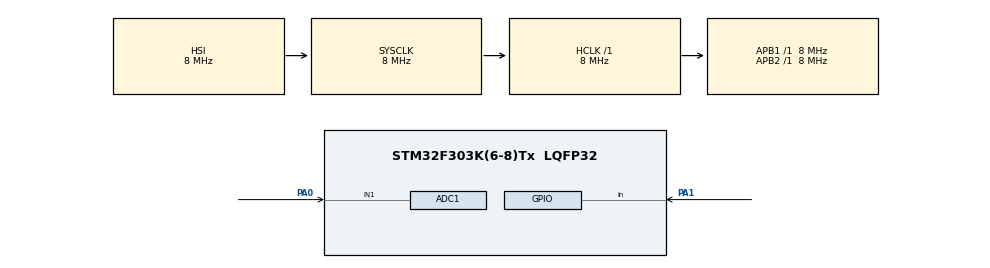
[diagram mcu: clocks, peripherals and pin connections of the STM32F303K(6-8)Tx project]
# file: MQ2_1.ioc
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ADC1.Channel-0\#ChannelRegularConversion=ADC_CHANNEL_1
ADC1.NbrOfConversionFlag=1
ADC1.Offset-0\#ChannelRegularConversion=0
ADC1.OffsetNumber-0\#ChannelRegularConversion=ADC_OFFSET_NONE
ADC1.Rank-0\#ChannelRegularConversion=1
ADC1.SamplingTime-0\#ChannelRegularConversion=ADC_SAMPLETIME_181CYCLES_5
ADC1.SamplingTimeOPAMP-0\#ChannelRegularConversion=ADC_SAMPLETIME_4CYCLES_5
ADC1.SubFamily=STM32F303x8
ADC1.master=1
Mcu.Family=STM32F3
Mcu.Name=STM32F303K(6-8)Tx
Mcu.Package=LQFP32
NVIC.PriorityGroup=NVIC_PRIORITYGROUP_4
PA0.Mode=IN1-Single-Ended
PA0.Signal=ADC1_IN1
PA1.Signal=GPIO_Input
PA13.Mode=Trace_Asynchronous_SW
PA13.Signal=SYS_JTMS-SWDIO
PA14.Mode=Trace_Asynchronous_SW
PA14.Signal=SYS_JTCK-SWCLK
PB3.Mode=Trace_Asynchronous_SW
PB3.Signal=SYS_JTDO-TRACESWO
ProjectManager.HeapSize=0x200
ProjectManager.StackSize=0x400
ProjectManager.TargetToolchain=STM32CubeIDE
RCC.AHBFreq_Value=8000000
RCC.APB1Freq_Value=8000000
RCC.APB2Freq_Value=8000000
RCC.CortexFreq_Value=8000000
RCC.HSE_VALUE=8000000
RCC.HSI_VALUE=8000000
RCC.PLLMUL=RCC_PLL_MUL4
RCC.SYSCLKFreq_VALUE=8000000
board=custom

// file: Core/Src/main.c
/* USER CODE BEGIN Header */
/**
 ******************************************************************************
 * @file           : main.c
 * @brief          : Main program body
 ******************************************************************************
 * @attention
 *
 * Copyright (c) 2025 STMicroelectronics.
 * All rights reserved.
 *
 * This software is licensed under terms that can be found in the LICENSE file
 * in the root directory of this software component.
 * If no LICENSE file comes with this software, it is provided AS-IS.
 *
 ******************************************************************************
 */
/* USER CODE END Header */
#include "main.h"

/* USER CODE BEGIN Includes */
#include <stdio.h>

/* USER CODE END Includes */

ADC_HandleTypeDef hadc1;

void SystemClock_Config(void);
static void MX_GPIO_Init(void);
static void MX_ADC1_Init(void);
/* USER CODE BEGIN PFP */
// Semi-hosting will handle printf automatically
/* USER CODE END PFP */
extern void initialise_monitor_handles(void);

int main(void)
{

  /* MCU Configuration--------------------------------------------------------*/

  /* Reset of all peripherals, Initializes the Flash interface and the Systick. */
  HAL_Init();

  /* Configure the system clock */
  SystemClock_Config();

  /* Initialize all configured peripherals */
  MX_GPIO_Init();
  MX_ADC1_Init();
  /* USER CODE BEGIN 2 */
  initialise_monitor_handles();
  printf("MQ2 Gas Sensor Test Started\r\n");
  /* USER CODE END 2 */

  /* Infinite loop */
  while (1)
  {

    /* USER CODE BEGIN 3 */
    // Start ADC conversion
    HAL_ADC_Start(&hadc1);

    // Wait for conversion to complete
    if (HAL_ADC_PollForConversion(&hadc1, HAL_MAX_DELAY) == HAL_OK)
    {
      // Get the ADC value
      uint32_t adcValue = HAL_ADC_GetValue(&hadc1);

      // Convert to millivolts (integer math)
      uint32_t millivolts = (adcValue * 3300) / 4095;

      // Read digital output (DOUT) - change GPIO_PIN_1 to your actual DOUT pin
      GPIO_PinState doutState = HAL_GPIO_ReadPin(GPIOA, GPIO_PIN_1);

      // Print results with gas detection status
      if (doutState == GPIO_PIN_RESET)
      { // Assuming active low (common)
        printf("MQ2 - ADC: %lu, Voltage: %lu mV, DOUT: GAS DETECTED!\r\n", adcValue, millivolts);
      }
      else
      {
        printf("MQ2 - ADC: %lu, Voltage: %lu mV, DOUT: No gas\r\n", adcValue, millivolts);
      }
    }

    // Stop ADC
    HAL_ADC_Stop(&hadc1);

    // Wait 1 second before next reading
    HAL_Delay(1000);
    /* USER CODE END 3 */
  }
}

void SystemClock_Config(void)
{
  RCC_OscInitTypeDef RCC_OscInitStruct = {0};
  RCC_ClkInitTypeDef RCC_ClkInitStruct = {0};
  RCC_PeriphCLKInitTypeDef PeriphClkInit = {0};

  /** Initializes the RCC Oscillators according to the specified parameters
   * in the RCC_OscInitTypeDef structure.
   */
  RCC_OscInitStruct.OscillatorType = RCC_OSCILLATORTYPE_HSI;
  RCC_OscInitStruct.HSIState = RCC_HSI_ON;
  RCC_OscInitStruct.HSICalibrationValue = RCC_HSICALIBRATION_DEFAULT;
  RCC_OscInitStruct.PLL.PLLState = RCC_PLL_ON;
  RCC_OscInitStruct.PLL.PLLSource = RCC_PLLSOURCE_HSI;
  RCC_OscInitStruct.PLL.PLLMUL = RCC_PLL_MUL4;
  if (HAL_RCC_OscConfig(&RCC_OscInitStruct) != HAL_OK)
  {
    Error_Handler();
  }

  /** Initializes the CPU, AHB and APB buses clocks
   */
  RCC_ClkInitStruct.ClockType = RCC_CLOCKTYPE_HCLK | RCC_CLOCKTYPE_SYSCLK | RCC_CLOCKTYPE_PCLK1 | RCC_CLOCKTYPE_PCLK2;
  RCC_ClkInitStruct.SYSCLKSource = RCC_SYSCLKSOURCE_HSI;
  RCC_ClkInitStruct.AHBCLKDivider = RCC_SYSCLK_DIV1;
  RCC_ClkInitStruct.APB1CLKDivider = RCC_HCLK_DIV1;
  RCC_ClkInitStruct.APB2CLKDivider = RCC_HCLK_DIV1;

  if (HAL_RCC_ClockConfig(&RCC_ClkInitStruct, FLASH_LATENCY_0) != HAL_OK)
  {
    Error_Handler();
  }
  PeriphClkInit.PeriphClockSelection = RCC_PERIPHCLK_ADC12;
  PeriphClkInit.Adc12ClockSelection = RCC_ADC12PLLCLK_DIV1;
  if (HAL_RCCEx_PeriphCLKConfig(&PeriphClkInit) != HAL_OK)
  {
    Error_Handler();
  }
}

static void MX_ADC1_Init(void)
{

  ADC_MultiModeTypeDef multimode = {0};
  ADC_ChannelConfTypeDef sConfig = {0};

  /** Common config
   */
  hadc1.Instance = ADC1;
  hadc1.Init.ClockPrescaler = ADC_CLOCK_ASYNC_DIV1;
  hadc1.Init.Resolution = ADC_RESOLUTION_12B;
  hadc1.Init.ScanConvMode = ADC_SCAN_DISABLE;
  hadc1.Init.ContinuousConvMode = DISABLE;
  hadc1.Init.DiscontinuousConvMode = DISABLE;
  hadc1.Init.ExternalTrigConvEdge = ADC_EXTERNALTRIGCONVEDGE_NONE;
  hadc1.Init.ExternalTrigConv = ADC_SOFTWARE_START;
  hadc1.Init.DataAlign = ADC_DATAALIGN_RIGHT;
  hadc1.Init.NbrOfConversion = 1;
  hadc1.Init.DMAContinuousRequests = DISABLE;
  hadc1.Init.EOCSelection = ADC_EOC_SINGLE_CONV;
  hadc1.Init.LowPowerAutoWait = DISABLE;
  hadc1.Init.Overrun = ADC_OVR_DATA_OVERWRITTEN;
  if (HAL_ADC_Init(&hadc1) != HAL_OK)
  {
    Error_Handler();
  }

  /** Configure the ADC multi-mode
   */
  multimode.Mode = ADC_MODE_INDEPENDENT;
  if (HAL_ADCEx_MultiModeConfigChannel(&hadc1, &multimode) != HAL_OK)
  {
    Error_Handler();
  }

  /** Configure Regular Channel
   */
  sConfig.Channel = ADC_CHANNEL_1;
  sConfig.Rank = ADC_REGULAR_RANK_1;
  sConfig.SingleDiff = ADC_SINGLE_ENDED;
  sConfig.SamplingTime = ADC_SAMPLETIME_181CYCLES_5;
  sConfig.OffsetNumber = ADC_OFFSET_NONE;
  sConfig.Offset = 0;
  if (HAL_ADC_ConfigChannel(&hadc1, &sConfig) != HAL_OK)
  {
    Error_Handler();
  }
}

static void MX_GPIO_Init(void)
{
  GPIO_InitTypeDef GPIO_InitStruct = {0};

  /* GPIO Ports Clock Enable */
  __HAL_RCC_GPIOA_CLK_ENABLE();
  __HAL_RCC_GPIOB_CLK_ENABLE();

  /*Configure GPIO pin : PA1 */
  GPIO_InitStruct.Pin = GPIO_PIN_1;
  GPIO_InitStruct.Mode = GPIO_MODE_INPUT;
  GPIO_InitStruct.Pull = GPIO_NOPULL;
  HAL_GPIO_Init(GPIOA, &GPIO_InitStruct);

}

void Error_Handler(void)
{
  __disable_irq();
  while (1)
  {
  }
}
